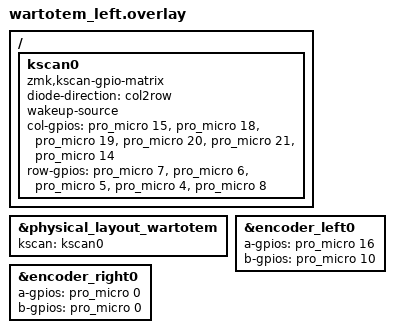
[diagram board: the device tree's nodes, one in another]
#include "wartotem.dtsi"

/ {
    kscan0: kscan0 {
        compatible = "zmk,kscan-gpio-matrix";
		                diode-direction = "col2row";
                wakeup-source;

        col-gpios
            = <&pro_micro 15 GPIO_OPEN_SOURCE>
            , <&pro_micro 18 GPIO_OPEN_SOURCE>
            , <&pro_micro 19 GPIO_OPEN_SOURCE>
            , <&pro_micro 20 GPIO_OPEN_SOURCE>
            , <&pro_micro 21 GPIO_OPEN_SOURCE>
            , <&pro_micro 14 GPIO_OPEN_SOURCE>
            ;

        row-gpios
            = <&pro_micro 7 (GPIO_ACTIVE_HIGH | GPIO_PULL_DOWN)>
            , <&pro_micro 6 (GPIO_ACTIVE_HIGH | GPIO_PULL_DOWN)>
            , <&pro_micro 5 (GPIO_ACTIVE_HIGH | GPIO_PULL_DOWN)>
            , <&pro_micro 4 (GPIO_ACTIVE_HIGH | GPIO_PULL_DOWN)>
            , <&pro_micro 8 (GPIO_ACTIVE_HIGH | GPIO_PULL_DOWN)>
            ;
    };
};

&physical_layout_wartotem {
    kscan = <&kscan0>;
};

&encoder_left0 {
    a-gpios = <&pro_micro 16 (GPIO_ACTIVE_HIGH | GPIO_PULL_UP)>;
    b-gpios = <&pro_micro 10 (GPIO_ACTIVE_HIGH | GPIO_PULL_UP)>;
    status = "okay";
};

// Assigning dummy pins to other part's encoders
// just to satisfy the devicetree requirements.
// No code will be compiled for these disabled encoders.
&encoder_right0 {
    a-gpios = <&pro_micro 0 (GPIO_ACTIVE_HIGH | GPIO_PULL_UP)>;
    b-gpios = <&pro_micro 0 (GPIO_ACTIVE_HIGH | GPIO_PULL_UP)>;
};

